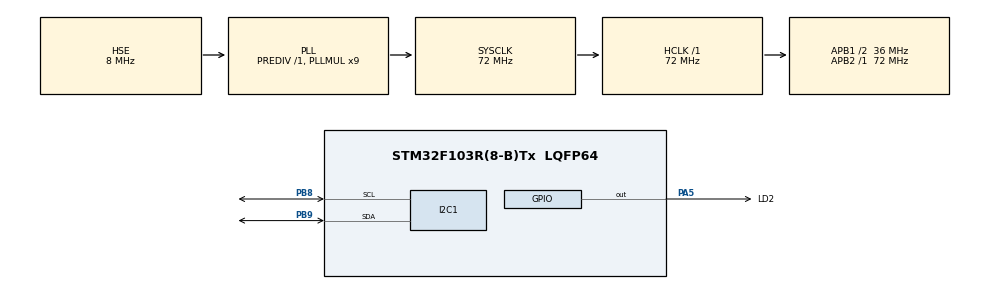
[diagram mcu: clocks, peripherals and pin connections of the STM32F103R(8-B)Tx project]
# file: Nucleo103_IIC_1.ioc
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Mcu.Family=STM32F1
Mcu.Name=STM32F103R(8-B)Tx
Mcu.Package=LQFP64
NVIC.PriorityGroup=NVIC_PRIORITYGROUP_4
PA13.Mode=Serial_Wire
PA13.Signal=SYS_JTMS-SWDIO
PA14.Mode=Serial_Wire
PA14.Signal=SYS_JTCK-SWCLK
PA5.GPIO_Label=LD2
PA5.Signal=GPIO_Output
PB8.Mode=I2C
PB8.Signal=I2C1_SCL
PB9.Mode=I2C
PB9.Signal=I2C1_SDA
PD0-OSC_IN.Mode=HSE-External-Oscillator
PD0-OSC_IN.Signal=RCC_OSC_IN
PD1-OSC_OUT.Mode=HSE-External-Oscillator
PD1-OSC_OUT.Signal=RCC_OSC_OUT
ProjectManager.HeapSize=0x200
ProjectManager.StackSize=0x400
ProjectManager.TargetToolchain=TrueSTUDIO
RCC.AHBFreq_Value=72000000
RCC.APB1CLKDivider=RCC_HCLK_DIV2
RCC.APB1Freq_Value=36000000
RCC.APB1TimFreq_Value=72000000
RCC.APB2Freq_Value=72000000
RCC.APB2TimFreq_Value=72000000
RCC.HCLKFreq_Value=72000000
RCC.PLLMUL=RCC_PLL_MUL9
RCC.PLLSourceVirtual=RCC_PLLSOURCE_HSE
RCC.SYSCLKFreq_VALUE=72000000
RCC.SYSCLKSource=RCC_SYSCLKSOURCE_PLLCLK
RCC.USBFreq_Value=72000000
board=custom

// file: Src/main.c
/* USER CODE BEGIN Header */
/**
  ******************************************************************************
  * @file           : main.c
  * @brief          : Main program body
  ******************************************************************************
  * @attention
  *
  * <h2><center>&copy; Copyright (c) 2020 STMicroelectronics.
  * All rights reserved.</center></h2>
  *
  * This software component is licensed by ST under BSD 3-Clause license,
  * the "License"; You may not use this file except in compliance with the
  * License. You may obtain a copy of the License at:
  *                        opensource.org/licenses/BSD-3-Clause
  *
  ******************************************************************************
  */
/* USER CODE END Header */

#include "main.h"

/* USER CODE BEGIN Includes */
#include "liquidcrystal_i2c.h"
/* USER CODE END Includes */

I2C_HandleTypeDef hi2c1;

void SystemClock_Config(void);
static void MX_GPIO_Init(void);
static void MX_I2C1_Init(void);

int main(void)
{
  /* USER CODE BEGIN 1 */
	//uint8_t data[1];
	//data[0] = 0x03;
  /* USER CODE END 1 */

  /* MCU Configuration--------------------------------------------------------*/

  /* Reset of all peripherals, Initializes the Flash interface and the Systick. */
  HAL_Init();

  /* Configure the system clock */
  SystemClock_Config();

  /* Initialize all configured peripherals */
  MX_GPIO_Init();
  MX_I2C1_Init();
  /* USER CODE BEGIN 2 */

  /* Initialize */
  HD44780_Init(2);

  HD44780_Clear();

  HD44780_NoDisplay();
  HD44780_Cursor();
  HD44780_SetCursor(0,0);
  //HD44780_PrintStr("HELLO STM32!!!");
  HD44780_PrintStr("Hello STM32Study");
  HD44780_PrintSpecialChar(0);

  /* Show characters */
  HD44780_Display();

	/* Move position */
	HD44780_SetCursor(0, 1);
	//HD44780_PrintStr("Bye STM32!!!");
	HD44780_PrintStr("Step by step!");
	HD44780_PrintSpecialChar(1);

	/* Blink cursor */
	HD44780_Blink();
  /* USER CODE END 2 */

  /* Infinite loop */
  while (1)
  {

    /* USER CODE BEGIN 3 */
  	HAL_GPIO_TogglePin(LD2_GPIO_Port, LD2_Pin);
  	HAL_Delay(50);
  }
  /* USER CODE END 3 */
}

void SystemClock_Config(void)
{
  RCC_OscInitTypeDef RCC_OscInitStruct = {0};
  RCC_ClkInitTypeDef RCC_ClkInitStruct = {0};

  /** Initializes the CPU, AHB and APB busses clocks
  */
  RCC_OscInitStruct.OscillatorType = RCC_OSCILLATORTYPE_HSE;
  RCC_OscInitStruct.HSEState = RCC_HSE_ON;
  RCC_OscInitStruct.HSEPredivValue = RCC_HSE_PREDIV_DIV1;
  RCC_OscInitStruct.HSIState = RCC_HSI_ON;
  RCC_OscInitStruct.PLL.PLLState = RCC_PLL_ON;
  RCC_OscInitStruct.PLL.PLLSource = RCC_PLLSOURCE_HSE;
  RCC_OscInitStruct.PLL.PLLMUL = RCC_PLL_MUL9;
  if (HAL_RCC_OscConfig(&RCC_OscInitStruct) != HAL_OK)
  {
    Error_Handler();
  }
  /** Initializes the CPU, AHB and APB busses clocks
  */
  RCC_ClkInitStruct.ClockType = RCC_CLOCKTYPE_HCLK|RCC_CLOCKTYPE_SYSCLK
                              |RCC_CLOCKTYPE_PCLK1|RCC_CLOCKTYPE_PCLK2;
  RCC_ClkInitStruct.SYSCLKSource = RCC_SYSCLKSOURCE_PLLCLK;
  RCC_ClkInitStruct.AHBCLKDivider = RCC_SYSCLK_DIV1;
  RCC_ClkInitStruct.APB1CLKDivider = RCC_HCLK_DIV2;
  RCC_ClkInitStruct.APB2CLKDivider = RCC_HCLK_DIV1;

  if (HAL_RCC_ClockConfig(&RCC_ClkInitStruct, FLASH_LATENCY_2) != HAL_OK)
  {
    Error_Handler();
  }
}

static void MX_I2C1_Init(void)
{

  hi2c1.Instance = I2C1;
  hi2c1.Init.ClockSpeed = 100000;
  hi2c1.Init.DutyCycle = I2C_DUTYCYCLE_2;
  hi2c1.Init.OwnAddress1 = 0;
  hi2c1.Init.AddressingMode = I2C_ADDRESSINGMODE_7BIT;
  hi2c1.Init.DualAddressMode = I2C_DUALADDRESS_DISABLE;
  hi2c1.Init.OwnAddress2 = 0;
  hi2c1.Init.GeneralCallMode = I2C_GENERALCALL_DISABLE;
  hi2c1.Init.NoStretchMode = I2C_NOSTRETCH_DISABLE;
  if (HAL_I2C_Init(&hi2c1) != HAL_OK)
  {
    Error_Handler();
  }

}

static void MX_GPIO_Init(void)
{
  GPIO_InitTypeDef GPIO_InitStruct = {0};

  /* GPIO Ports Clock Enable */
  __HAL_RCC_GPIOD_CLK_ENABLE();
  __HAL_RCC_GPIOA_CLK_ENABLE();
  __HAL_RCC_GPIOB_CLK_ENABLE();

  /*Configure GPIO pin Output Level */
  HAL_GPIO_WritePin(LD2_GPIO_Port, LD2_Pin, GPIO_PIN_RESET);

  /*Configure GPIO pin : LD2_Pin */
  GPIO_InitStruct.Pin = LD2_Pin;
  GPIO_InitStruct.Mode = GPIO_MODE_OUTPUT_PP;
  GPIO_InitStruct.Pull = GPIO_NOPULL;
  GPIO_InitStruct.Speed = GPIO_SPEED_FREQ_LOW;
  HAL_GPIO_Init(LD2_GPIO_Port, &GPIO_InitStruct);

}

void Error_Handler(void)
{
}

/************************ (C) COPYRIGHT STMicroelectronics *****END OF FILE****/
